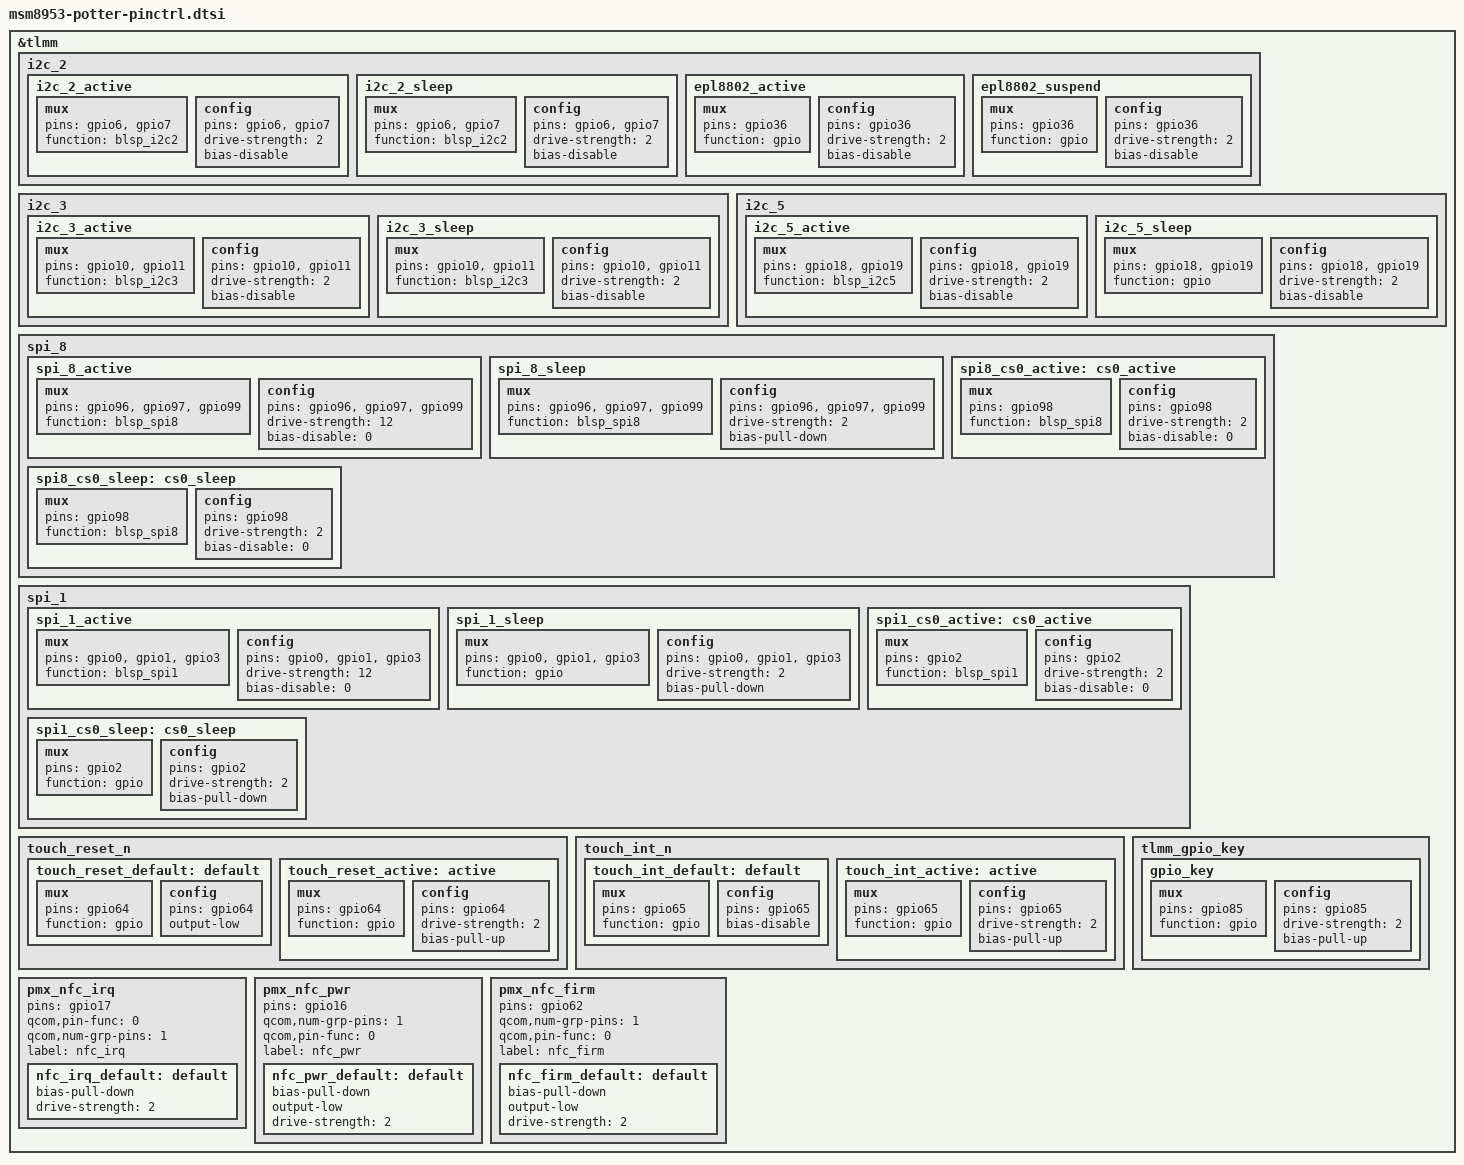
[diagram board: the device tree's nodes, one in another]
/* Copyright (c) 2016, Motorola Mobility Inc. All rights reserved.
 *
 * This program is free software; you can redistribute it and/or modify
 * it under the terms of the GNU General Public License version 2 and
 * only version 2 as published by the Free Software Foundation.
 *
 * This program is distributed in the hope that it will be useful,
 * but WITHOUT ANY WARRANTY; without even the implied warranty of
 * MERCHANTABILITY or FITNESS FOR A PARTICULAR PURPOSE.  See the
 * GNU General Public License for more details.
 */

&tlmm{
	i2c_2 {
		i2c_2_active: i2c_2_active {
			/* active state */
			mux {
				pins = "gpio6", "gpio7";
				function = "blsp_i2c2";
			};

			config {
				pins = "gpio6", "gpio7";
				drive-strength = <2>;
				bias-disable; /* No PULL */
			};
		};

		i2c_2_sleep: i2c_2_sleep {
			/* suspended state */
			mux {
				pins = "gpio6", "gpio7";
				function = "blsp_i2c2";
			};

			config {
				pins = "gpio6", "gpio7";
				drive-strength = <2>;
				bias-disable;/* No PULL */
			};
		};

		epl8802_active: epl8802_active{
			/* active state */
			mux {
				pins = "gpio36";
				function = "gpio";
			};

			config {
				pins = "gpio36";
				drive-strength = <2>;
				bias-disable; /* No PULL */
			};
		};

		epl8802_suspend: epl8802_suspend{
			mux {
				pins = "gpio36";
				function = "gpio";
			};

			config {
				pins = "gpio36";
				drive-strength = <2>;
				bias-disable; /* No PULL */
			};
		};
	};

	i2c_3 {
		i2c_3_active: i2c_3_active {
			/* active state */
			mux {
				pins = "gpio10", "gpio11";
				function = "blsp_i2c3";
			};

			config {
				pins = "gpio10", "gpio11";
				drive-strength = <2>;
				bias-disable;
			};
		};

		i2c_3_sleep: i2c_3_sleep {
			/* suspended state */
			mux {
				pins = "gpio10", "gpio11";
				function = "blsp_i2c3";
			};

			config {
				pins = "gpio10", "gpio11";
				drive-strength = <2>;
				bias-disable;
			};
		};
	};

	i2c_5 {
		i2c_5_active: i2c_5_active {
			/* active state */
			mux {
				pins = "gpio18", "gpio19";
				function = "blsp_i2c5";
			};

			config {
				pins = "gpio18", "gpio19";
				drive-strength = <2>;
				bias-disable;
			};
		};

		i2c_5_sleep: i2c_5_sleep {
			/* suspended state */
			mux {
				pins = "gpio18", "gpio19";
				function = "gpio";
			};

			config {
				pins = "gpio18", "gpio19";
				drive-strength = <2>;
				bias-disable;
			};
		};
	};

	spi_8 {
		spi_8_active: spi_8_active {
			mux {
				/* MOSI, MISO, CLK */
				pins = "gpio96", "gpio97", "gpio99";
				function = "blsp_spi8";
			};

			config {
				pins = "gpio96", "gpio97", "gpio99";
				drive-strength = <12>; /* 12 MA */
				bias-disable = <0>; /* No PULL */
			};
		};

		spi_8_sleep: spi_8_sleep {
			mux {
				/* MOSI, MISO, CLK */
				pins = "gpio96", "gpio97", "gpio99";
				function = "blsp_spi8";
			};

			config {
				pins = "gpio96", "gpio97", "gpio99";
				drive-strength = <2>; /* 2 MA */
				bias-pull-down; /* PULL Down */
			};
		};

		spi8_cs0_active: cs0_active {
			mux {
				pins = "gpio98";
				function = "blsp_spi8";
			};

			config {
				pins = "gpio98";
				drive-strength = <2>;
				bias-disable = <0>;
			};
		};

		spi8_cs0_sleep: cs0_sleep {
			mux {
				pins = "gpio98";
				function = "blsp_spi8";
			};

			config {
				pins = "gpio98";
				drive-strength = <2>;
				bias-disable = <0>;
			};
		};
	};

	spi_1 {
		spi_1_active: spi_1_active {
			mux {
				/* MOSI, MISO, CLK */
				pins = "gpio0", "gpio1", "gpio3";
				function = "blsp_spi1";
			};

			config {
				pins = "gpio0", "gpio1", "gpio3";
				drive-strength = <12>; /* 12 MA */
				bias-disable = <0>; /* No PULL */
			};
		};

		spi_1_sleep: spi_1_sleep {
			mux {
				/* MOSI, MISO, CLK */
				pins = "gpio0", "gpio1", "gpio3";
				function = "gpio";
			};

			config {
				pins = "gpio0", "gpio1", "gpio3";
				drive-strength = <2>; /* 2 MA */
				bias-pull-down; /* PULL Down */
			};
		};

		spi1_cs0_active: cs0_active {
			mux {
				pins = "gpio2";
				function = "blsp_spi1";
			};

			config {
				pins = "gpio2";
				drive-strength = <2>;
				bias-disable = <0>;
			};
		};

		spi1_cs0_sleep: cs0_sleep {
			mux {
				pins = "gpio2";
				function = "gpio";
			};

			config {
				pins = "gpio2";
				drive-strength = <2>;
				bias-pull-down;
			};
		};
	};

/*
	cs35l34_reset_default: cs35l34_reset_default {  // vexter and potter use the same device?
		config {
			pins = "gpio94";
			output-high;
			bias-pull-up;
			drive-strength = <2>;
		};
	};
*/

/*
	marley_irq_default: marley_irq_default {  //SAR_SENSOR_INT_N
		config {
			pins = "gpio46";
			drive-strength = <2>;
			bias-pull-up;
		};
	};
*/

	touch_reset_n {
		/*label = "touch-reset";*/

		touch_reset_default: default {
			mux {
				pins = "gpio64";
				function = "gpio";
			};

			config {
				pins = "gpio64";
				output-low;
			};
		};

		touch_reset_active: active {
			mux {
				pins = "gpio64";
				function = "gpio";
			};

			config {
				pins = "gpio64";
				drive-strength = <2>;   /* 2 mA */
				bias-pull-up; /* pull-up */
			};
		};
	};

	touch_int_n {
		/*label = "touch-int";*/

		touch_int_default: default {
			mux {
				pins = "gpio65";
				function = "gpio";
			};

			config {
				pins = "gpio65";
				bias-disable;
			};
		};

		touch_int_active: active {
			mux {
				pins = "gpio65";
				function = "gpio";
			};

			config {
				pins = "gpio65";
				drive-strength = <2>;
				bias-pull-up; /* pull-up */
			};
		};
	};

	/delete-node/ tlmm_gpio_key;
	tlmm_gpio_key {
		gpio_key: gpio_key {
			mux {
				pins = "gpio85";
				function = "gpio";
			};
			config {
				pins = "gpio85";
				drive-strength = <2>;
				bias-pull-up;
			};
		};
	};

	pmx_nfc_irq {
		pins = "gpio17";
		qcom,pin-func = <0>;
		qcom,num-grp-pins = <1>;
		label = "nfc_irq";

		nfc_irq_default: default {
			bias-pull-down;
			drive-strength = <2>;
		};
	};

	pmx_nfc_pwr {
		pins = "gpio16";
		qcom,num-grp-pins = <1>;
		qcom,pin-func = <0>;
		label = "nfc_pwr";

		nfc_pwr_default: default {
			bias-pull-down;
			output-low;
			drive-strength = <2>;
		};
	};

	pmx_nfc_firm {
		pins = "gpio62";
		qcom,num-grp-pins = <1>;
		qcom,pin-func = <0>;
		label = "nfc_firm";

		nfc_firm_default: default {
			bias-pull-down;
			output-low;
			drive-strength = <2>;
		};
	};

};

/delete-node/ &hsuart_active;
/delete-node/ &hsuart_sleep;
